# SF32LB57x register map
File version: 1.0
CPU: CM33 r0p1, little endian, MPU, FPU, 3 interrupt priority bits
Registers are 32-bit, read-write, reset 0x0 unless marked. A register's access mark holds for its fields unless they carry their own. Offsets are from the block's base; [hi:lo] are bit positions; {n}, {i} and the like mark numbered series.

## HPSYS_CFG
Base 0x5000B000
0x00 BMR — Boot Mode Register
  [0] BOOT_MODE — 0 - normal boot; 1 - download mode
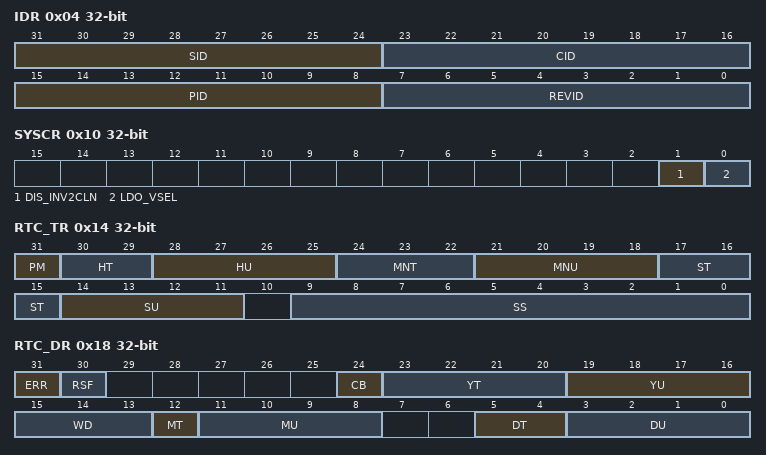
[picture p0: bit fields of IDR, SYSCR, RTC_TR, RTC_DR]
0x04 IDR — ID Register
  [31:24] SID — Series ID
  [23:16] CID — Chip ID
  [15:8] PID — Package ID
  [7:0] REVID — ECO Revision ID
0x08 SWCR — SW Control Register
  [0] SWSEL — 0 - SW connected to HCPU; 1 - SW connected to LCPU
0x0C SCR — Security Control Register
  [0] FKEY_MODE — AES will use dedicated algorithm for root key encryption and will not output to SRAM
0x10 SYSCR — System Configure Register
  [1] DIS_INV2CLN — Disable clean cache when invalidate cache
  [0] LDO_VSEL — Shortcut to select LDO voltage
0x14 RTC_TR — RTC Time Register
  [31] PM, [30:29] HT, [28:25] HU, [24:22] MNT, [21:18] MNU, [17:15] ST, [14:11] SU, [9:0] SS
0x18 RTC_DR — RTC Date Register
  [31] ERR
  [30] RSF — re-sync flag. Write 0 to clear, write 1 has no effect. Auto-cleared when entering low power mode
  [24] CB
  [23:20] YT
  [19:16] YU
  [15:13] WD
  [12] MT
  [11:8] MU
  [5:4] DT
  [3:0] DU
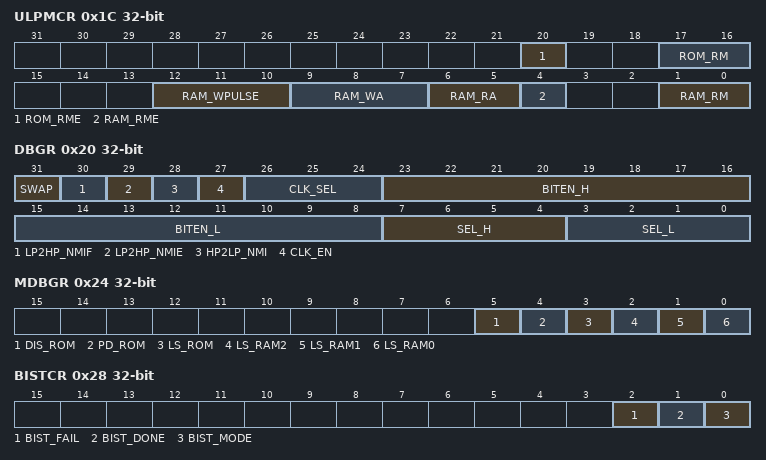
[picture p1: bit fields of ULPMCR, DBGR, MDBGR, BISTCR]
0x1C ULPMCR — ULP Memory Control register
  [20] ROM_RME, [17:16] ROM_RM, [12:10] RAM_WPULSE, [9:7] RAM_WA, [6:5] RAM_RA, [4] RAM_RME, [1:0] RAM_RM
0x20 DBGR — Debug Select Register
  [31] SWAP — Swap upper/lower byte of debug data
  [30] LP2HP_NMIF — LP2HP NMI interrupt flag
  [29] LP2HP_NMIE — LP2HP NMI interrupt enable
  [28] HP2LP_NMI — set 1 to send NMI interrupt to LCPU
  [27] CLK_EN
  [26:24] CLK_SEL
  [23:16] BITEN_H — bit enable for debug data higher byte, active high
  [15:8] BITEN_L — bit enable for debug data lower byte, active high
  [7:4] SEL_H — select higher byte of debug data
  [3:0] SEL_L — select lower byte of debug data
0x24 MDBGR — Memory Debug Register
  [5] DIS_ROM
  [4] PD_ROM — Power down ROM during deep sleep
  [3] LS_ROM — Force ROM into Light Sleep mode during active
  [2] LS_RAM2
  [1] LS_RAM1
  [0] LS_RAM0 — Force RAM0 into Light Sleep mode during active
0x28 BISTCR — Bist Control Register
  [2] BIST_FAIL — All-in-one BIST fail flag
  [1] BIST_DONE — All-in-one BIST done flag
  [0] BIST_MODE — Set 1 to enable BIST mode
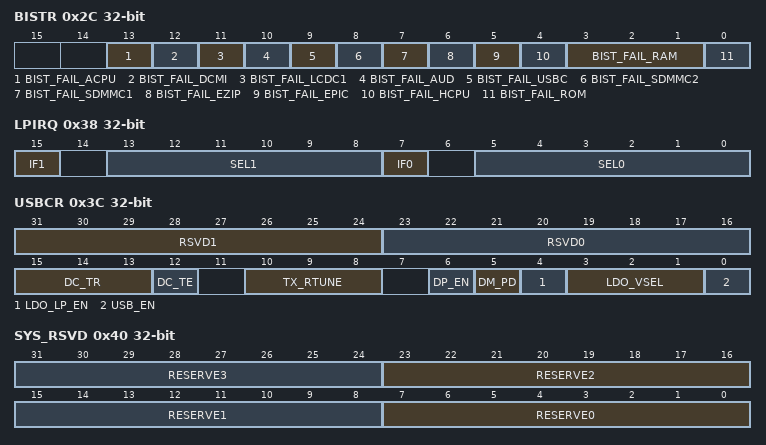
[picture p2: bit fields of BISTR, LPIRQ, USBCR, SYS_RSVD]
0x2C BISTR — Bist Result Register
  [13] BIST_FAIL_ACPU, [12] BIST_FAIL_DCMI, [11] BIST_FAIL_LCDC1, [10] BIST_FAIL_AUD, [9] BIST_FAIL_USBC, [8] BIST_FAIL_SDMMC2, [7] BIST_FAIL_SDMMC1, [6] BIST_FAIL_EZIP, [5] BIST_FAIL_EPIC, [4] BIST_FAIL_HCPU, [3:1] BIST_FAIL_RAM, [0] BIST_FAIL_ROM
0x30 ROMCR0 — ROM Compare Register 0
  [31:0] SIG — HCPU ROM signature
0x34 ROMCR1 — ROM Compare Register 1
  [31:0] SIG — AUDPRC ROM signature
0x38 LPIRQ — Interrupt Selection for LCPU
  [15] IF1 — hp2lp_irq[1] status. Write 1 clear
  [13:8] SEL1 — select hp2lp_irq[1]
  [7] IF0 — hp2lp_irq[0] status. Write 1 clear
  [5:0] SEL0 — select hp2lp_irq[0]
0x3C USBCR — USB Control register
  [31:24] RSVD1 — reserve bit for USB11 PHY
  [23:16] RSVD0 — reserve bit for USB11 PHY
  [15:13] DC_TR — DC test point select
  [12] DC_TE — PMU DC test Macro select
  [10:8] TX_RTUNE — TX outp impedance tuning 0 = 50 Ohm, 1 = 46 Ohm, 2 = 43 Ohm, 3 = 40 Ohm, 4 = 37.5 Ohm, 5 = 35 Ohm, 6 = 33 Ohm, 7 = 31.5 Ohm
  [6] DP_EN — 0:disable dp pull up or pull down 1:enable dp pull or pull down
  [5] DM_PD — enable DM 15k Ohm pull down resistor
  [4] LDO_LP_EN — 2.5V LDO low power mode enable. 0 = 240 uA, 1 = 50 uA
  [3:1] LDO_VSEL — 2.5V LDO output voltage setting 0 = 2.40 V, 1 = 2.47 V, 2 = 2.53 V, 3 = 2.60 V, 4 = 2.60 V, 5 = 2.67 V, 6 = 2.73 V, 7 = 2.8 V
  [0] USB_EN — USB PHY enable, turn on power swith, power up LDO and bias
0x40 SYS_RSVD — HPSYS RSVD Register
  [8n+7:8n] RESERVE{n} (n=0..3)
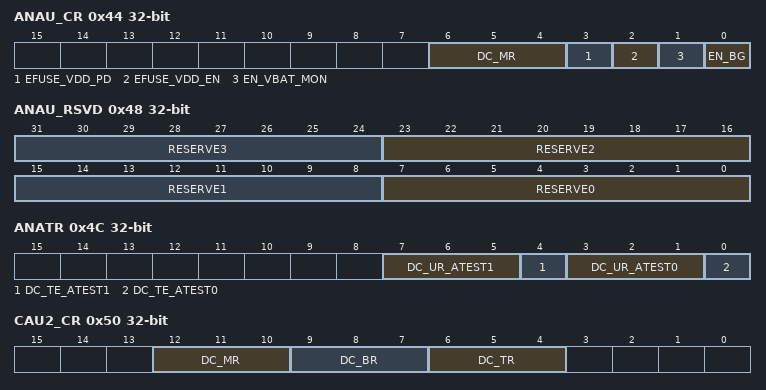
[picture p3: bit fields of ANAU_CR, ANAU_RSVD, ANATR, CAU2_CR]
0x44 ANAU_CR — ANAU Control Register
  [6:4] DC_MR
  [3] EFUSE_VDD_PD — efuse VDD pull-down
  [2] EFUSE_VDD_EN — efuse VDD enable
  [1] EN_VBAT_MON — enable VBAT monitor
  [0] EN_BG
0x48 ANAU_RSVD — ANAU Reserve Register
  [8n+7:8n] RESERVE{n} (n=0..3)
0x4C ANATR — Analog Test Register
  [7:5] DC_UR_ATEST1, [4] DC_TE_ATEST1, [3:1] DC_UR_ATEST0, [0] DC_TE_ATEST0
0x50 CAU2_CR — CAU2 Control Register
  [12:10] DC_MR, [9:7] DC_BR, [6:4] DC_TR
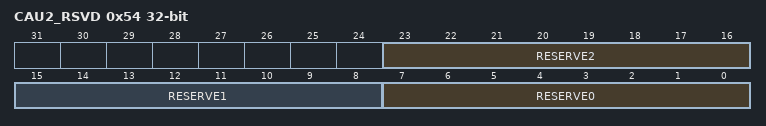
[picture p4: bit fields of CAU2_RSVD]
0x54 CAU2_RSVD — CAU2 RSVD Register1
  [23:16] RESERVE2, [15:8] RESERVE1, [7:0] RESERVE0
